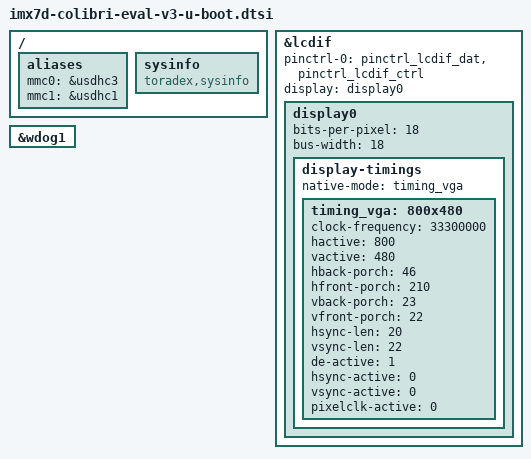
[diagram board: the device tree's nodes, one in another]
// SPDX-License-Identifier: GPL-2.0-or-later OR MIT
/*
 * Copyright 2020-2022 Toradex
 */

#include "imx7s-u-boot.dtsi"

/ {
	aliases {
		/* SDHCI instance order: eMMC, SD/MMC */
		mmc0 = &usdhc3;
		mmc1 = &usdhc1;
	};

	sysinfo {
		compatible = "toradex,sysinfo";
	};
};

&lcdif {
	status = "okay";
	pinctrl-names = "default";
	pinctrl-0 = <&pinctrl_lcdif_dat
		     &pinctrl_lcdif_ctrl>;
	display = <&display0>;
	bootph-all;

	display0: display0 {
		bits-per-pixel = <18>;
		bus-width = <18>;
		status = "okay";

		display-timings {
			native-mode = <&timing_vga>;
			timing_vga: 800x480 {
				clock-frequency = <33300000>;
				hactive = <800>;
				vactive = <480>;
				hback-porch = <46>;
				hfront-porch = <210>;
				vback-porch = <23>;
				vfront-porch = <22>;
				hsync-len = <20>;
				vsync-len = <22>;

				de-active = <1>;
				hsync-active = <0>;
				vsync-active = <0>;
				pixelclk-active = <0>;
			};
		};
	};
};

&wdog1 {
	bootph-pre-ram;
};
